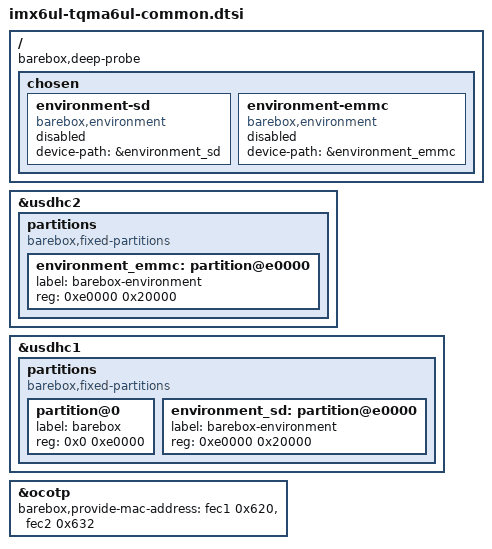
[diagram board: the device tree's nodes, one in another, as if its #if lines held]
// SPDX-License-Identifier: (GPL-2.0-or-later OR MIT)
/*
 * Copyright 2021 Pengutronix e.K.
 * Author: Rouven Czerwinski
 */

#include "imx6ul.dtsi"

/ {
	barebox,deep-probe;

	chosen {
		environment-sd {
			compatible = "barebox,environment";
			device-path = &environment_sd;
			status = "disabled";
		};
		environment-emmc {
			compatible = "barebox,environment";
			device-path = &environment_emmc;
			status = "disabled";
		};
	};
};

&usdhc2 {
	partitions {
		compatible = "barebox,fixed-partitions";
		#address-cells = <1>;
		#size-cells = <1>;

		environment_emmc: partition@e0000 {
			label = "barebox-environment";
			reg = <0xe0000 0x20000>;
		};
	};
};

&usdhc1 {
	partitions {
		compatible = "barebox,fixed-partitions";
		#address-cells = <1>;
		#size-cells = <1>;

		partition@0 {
			label = "barebox";
			reg = <0x0 0xe0000>;
		};

		environment_sd: partition@e0000 {
			label = "barebox-environment";
			reg = <0xe0000 0x20000>;
		};
	};
};

&ocotp {
	barebox,provide-mac-address = <&fec1 0x620 &fec2 0x632>;
};

/* include the FIT public key for verifying on demand */
#ifdef CONFIG_BOOTM_FITIMAGE_PUBKEY
#include CONFIG_BOOTM_FITIMAGE_PUBKEY
#endif
